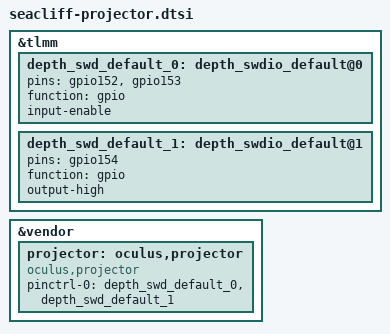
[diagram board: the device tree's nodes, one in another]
&tlmm {
	depth_swd_default_0: depth_swdio_default@0 {
		pins = "gpio152", "gpio153";
		function = "gpio";
		input-enable;
	};

	depth_swd_default_1: depth_swdio_default@1 {
		pins = "gpio154";
		function = "gpio";
		output-high;
	};
};

&vendor {
	projector: oculus,projector {
	status = "ok";
	compatible = "oculus,projector";
	pinctrl-names = "default";
	pinctrl-0 = <&depth_swd_default_0 &depth_swd_default_1>;
	};
};
